# bao1x register map
Vendor: baochip; File version: 1.0
Registers are 32-bit, read-write, reset 0x0 unless marked. A register's access mark holds for its fields unless they carry their own. Offsets are from the block's base; [hi:lo] are bit positions; <NAME> marks a mode.

## COMBOHASH
Base 0x4002B000
0x00 SFR_CRFUNC — See `combohasha.sv#L208 <https://github.com/baochip/baochip-1x/blob/main/rtl/mod ules/crypto_top/rtl/combohasha.sv#L208>`__ (line numbers are approximate)
  [7:0] cr_func — cr_func read/write control register
0x04 SFR_AR — See `combohasha.sv#L209 <https://github.com/baochip/baochip-1x/blob/main/rtl/mod ules/crypto_top/rtl/combohasha.sv#L209>`__ (line numbers are approximate)
  [31:0] sfr_ar — sfr_ar performs action on write of value: 0x5a
0x08 SFR_SRMFSM — See `combohasha.sv#L210 <https://github.com/baochip/baochip-1x/blob/main/rtl/mod ules/crypto_top/rtl/combohasha.sv#L210>`__ (line numbers are approximate)
  [7:0] mfsm — mfsm read only status register
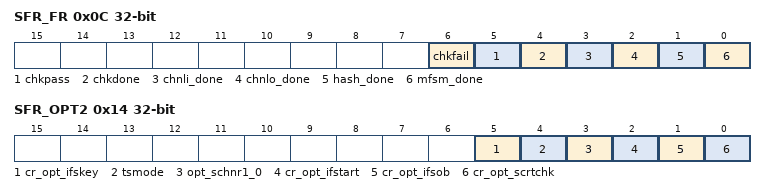
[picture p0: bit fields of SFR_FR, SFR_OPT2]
0x0C SFR_FR — See `combohasha.sv#L211 <https://github.com/baochip/baochip-1x/blob/main/rtl/mod ules/crypto_top/rtl/combohasha.sv#L211>`__ (line numbers are approximate)
  [6] chkfail — chkfail flag register. `1` means event happened, write back `1` in respective bit position to clear the flag
  [5] chkpass — chkpass flag register. `1` means event happened, write back `1` in respective bit position to clear the flag
  [4] chkdone — chkdone flag register. `1` means event happened, write back `1` in respective bit position to clear the flag
  [3] chnli_done — chnli_done flag register. `1` means event happened, write back `1` in respective bit position to clear the flag
  [2] chnlo_done — chnlo_done flag register. `1` means event happened, write back `1` in respective bit position to clear the flag
  [1] hash_done — hash_done flag register. `1` means event happened, write back `1` in respective bit position to clear the flag
  [0] mfsm_done — mfsm_done flag register. `1` means event happened, write back `1` in respective bit position to clear the flag
0x10 SFR_OPT1 — See `combohasha.sv#L213 <https://github.com/baochip/baochip-1x/blob/main/rtl/mod ules/crypto_top/rtl/combohasha.sv#L213>`__ (line numbers are approximate)
  [15:0] cr_opt_hashcnt — cr_opt_hashcnt read/write control register
0x14 SFR_OPT2 — See `combohasha.sv#L214 <https://github.com/baochip/baochip-1x/blob/main/rtl/mod ules/crypto_top/rtl/combohasha.sv#L214>`__ (line numbers are approximate)
  [5] cr_opt_ifskey — cr_opt.ifskey read/write control register
  [4] tsmode — tsmode read/write control register
  [3] opt_schnr1_0 — opt_schnr[1:0] read/write control register
  [2] cr_opt_ifstart — cr_opt.ifstart read/write control register
  [1] cr_opt_ifsob — cr_opt.ifsob read/write control register
  [0] cr_opt_scrtchk — cr_opt.scrtchk read/write control register
0x18 SFR_OPT3 — See `combohasha.sv#L215 <https://github.com/baochip/baochip-1x/blob/main/rtl/mod ules/crypto_top/rtl/combohasha.sv#L215>`__ (line numbers are approximate)
  [7:0] sfr_opt3 — sfr_opt3 read/write control register
0x1C SFR_BLKT0 — See `combohasha.sv#L216 <https://github.com/baochip/baochip-1x/blob/main/rtl/mod ules/crypto_top/rtl/combohasha.sv#L216>`__ (line numbers are approximate)
  [7:0] sfr_blkt0 — sfr_blkt0 read/write control register
0x20 SFR_SEGPTR_SEGID_LKEY — See `combohasha.sv#L219 <https://github.com/baochip/baochip-1x/blob/main/rtl/mod ules/crypto_top/rtl/combohasha.sv#L219>`__ (line numbers are approximate)
  [11:0] SEGID_LKEY — cr_segptrstart read/write control register
0x24 SFR_SEGPTR_SEGID_KEY — See `combohasha.sv#L219 <https://github.com/baochip/baochip-1x/blob/main/rtl/mod ules/crypto_top/rtl/combohasha.sv#L219>`__ (line numbers are approximate)
  [11:0] SEGID_KEY — cr_segptrstart read/write control register
0x2C SFR_SEGPTR_SEGID_SCRT — See `combohasha.sv#L219 <https://github.com/baochip/baochip-1x/blob/main/rtl/mod ules/crypto_top/rtl/combohasha.sv#L219>`__ (line numbers are approximate)
  [11:0] SEGID_SCRT — cr_segptrstart read/write control register
0x30 SFR_SEGPTR_SEGID_MSG — See `combohasha.sv#L219 <https://github.com/baochip/baochip-1x/blob/main/rtl/mod ules/crypto_top/rtl/combohasha.sv#L219>`__ (line numbers are approximate)
  [11:0] SEGID_MSG — cr_segptrstart read/write control register
0x34 SFR_SEGPTR_SEGID_HOUT — See `combohasha.sv#L219 <https://github.com/baochip/baochip-1x/blob/main/rtl/mod ules/crypto_top/rtl/combohasha.sv#L219>`__ (line numbers are approximate)
  [11:0] SEGID_HOUT — cr_segptrstart read/write control register
0x3C SFR_SEGPTR_SEGID_HOUT2 — See `combohasha.sv#L219 <https://github.com/baochip/baochip-1x/blob/main/rtl/mod ules/crypto_top/rtl/combohasha.sv#L219>`__ (line numbers are approximate)
  [11:0] SEGID_HOUT2 — cr_segptrstart read/write control register
0x60 SFR_KEYIDX — See `combohasha.sv#L217 <https://github.com/baochip/baochip-1x/blob/main/rtl/mod ules/crypto_top/rtl/combohasha.sv#L217>`__ (line numbers are approximate)
  [9:0] sfr_keyidx — sfr_keyidx read/write control register
